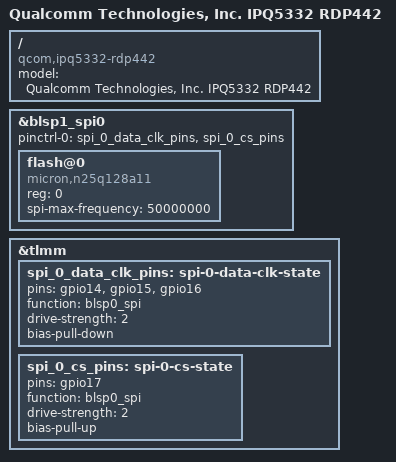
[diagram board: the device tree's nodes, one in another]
// SPDX-License-Identifier: GPL-2.0-only
/*
 * Copyright (c) Qualcomm Technologies, Inc. and/or its subsidiaries.
 */

/dts-v1/;

#include "ipq5332-rdp-common.dtsi"

/ {
	model = "Qualcomm Technologies, Inc. IPQ5332 RDP442";
	compatible = "qcom,ipq5332-rdp442", "qcom,ipq5332";
};

&blsp1_spi0 {
	pinctrl-0 = <&spi_0_data_clk_pins &spi_0_cs_pins>;
	pinctrl-names = "default";
	status = "okay";

	flash@0 {
		compatible = "micron,n25q128a11", "jedec,spi-nor";
		reg = <0>;
		#address-cells = <1>;
		#size-cells = <1>;
		spi-max-frequency = <50000000>;
	};
};

&tlmm {
	spi_0_data_clk_pins: spi-0-data-clk-state {
		pins = "gpio14", "gpio15", "gpio16";
		function = "blsp0_spi";
		drive-strength = <2>;
		bias-pull-down;
	};

	spi_0_cs_pins: spi-0-cs-state {
		pins = "gpio17";
		function = "blsp0_spi";
		drive-strength = <2>;
		bias-pull-up;
	};
};
